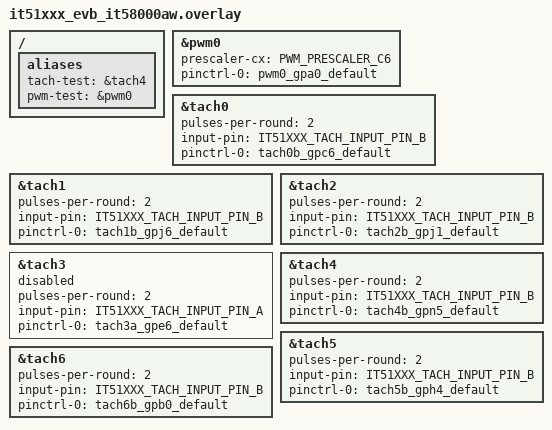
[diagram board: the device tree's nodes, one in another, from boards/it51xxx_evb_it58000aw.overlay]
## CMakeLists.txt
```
# SPDX-License-Identifier: Apache-2.0

cmake_minimum_required(VERSION 3.20.0)
find_package(Zephyr REQUIRED HINTS $ENV{ZEPHYR_BASE})
project(ite_tach)

FILE(GLOB app_sources src/*.c)
target_sources(app PRIVATE ${app_sources})
```

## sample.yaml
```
sample:
  name: ITE Tach Sensor
tests:
  sample.sensor.ite.tach:
    tags: sensors
    depends_on:
      - pwm
    platform_allow:
      - it8xxx2_evb
      - it82xx2_evb
      - it51xxx_evb/it51526aw
      - it51xxx_evb/it58000aw
```

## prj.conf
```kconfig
CONFIG_PWM=y
CONFIG_SENSOR=y
CONFIG_LOG=y
CONFIG_CBPRINTF_FP_SUPPORT=y
```

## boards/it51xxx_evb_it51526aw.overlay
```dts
/*
 * Copyright (c) 2026 ITE Corporation. All Rights Reserved.
 *
 * SPDX-License-Identifier: Apache-2.0
 */

/ {
	aliases {
		tach-test = &tach0;
		pwm-test = &pwm0;
	};
};

&pwm0 {
	status = "okay";
	prescaler-cx = <PWM_PRESCALER_C6>;
	pinctrl-0 = <&pwm0_gpa0_default>;
	pinctrl-names = "default";
};

&tach0 {
	status = "okay";
	pulses-per-round = <2>;
	/* IT51XXX_TACH_INPUT_PIN_A: tach0a_gpd6_default
	 * IT51XXX_TACH_INPUT_PIN_B: tach0b_gpc6_default
	 */
	input-pin = <IT51XXX_TACH_INPUT_PIN_B>;
	pinctrl-0 = <&tach0b_gpc6_default>;
	pinctrl-names = "default";
};
```

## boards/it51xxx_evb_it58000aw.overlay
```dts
/*
 * Copyright (c) 2026 ITE Corporation. All Rights Reserved.
 *
 * SPDX-License-Identifier: Apache-2.0
 */

/ {
	aliases {
		tach-test = &tach4;
		pwm-test = &pwm0;
	};
	/* for tach3 test */
	/*
	chosen {
		zephyr,console = &uart2;
		zephyr,shell-uart = &uart2;
	};
	*/
};

/* for tach3 test */
/*
&uart1 {
	status = "disabled";
};

&uart2 {
	status = "okay";
	current-speed = <115200>;
	clock-frequency = <1843200>;
	pinctrl-0 = <&uart2_rx_gph1_default
		     &uart2_tx_gph2_default>;
	pinctrl-names = "default";
};
*/

&pwm0 {
	status = "okay";
	prescaler-cx = <PWM_PRESCALER_C6>;
	pinctrl-0 = <&pwm0_gpa0_default>;
	pinctrl-names = "default";
};

&tach0 {
	status = "okay";
	pulses-per-round = <2>;
	/* IT51XXX_TACH_INPUT_PIN_A: tach0a_gpd6_default
	 * IT51XXX_TACH_INPUT_PIN_B: tach0b_gpc6_default
	 */
	input-pin = <IT51XXX_TACH_INPUT_PIN_B>;
	pinctrl-0 = <&tach0b_gpc6_default>;
	pinctrl-names = "default";
};

&tach1 {
	status = "okay";
	pulses-per-round = <2>;
	/* IT51XXX_TACH_INPUT_PIN_A: tach1a_gpd7_default
	 * IT51XXX_TACH_INPUT_PIN_B: tach1b_gpj6_default
	 */
	input-pin = <IT51XXX_TACH_INPUT_PIN_B>;
	pinctrl-0 = <&tach1b_gpj6_default>;
	pinctrl-names = "default";
};

&tach2 {
	status = "okay";
	pulses-per-round = <2>;
	/* IT51XXX_TACH_INPUT_PIN_A: tach2a_gpj0_default
	 * IT51XXX_TACH_INPUT_PIN_B: tach2b_gpj1_default
	 */
	input-pin = <IT51XXX_TACH_INPUT_PIN_B>;
	pinctrl-0 = <&tach2b_gpj1_default>;
	pinctrl-names = "default";
};

&tach3 {
	status = "disabled";
	pulses-per-round = <2>;
	/* IT51XXX_TACH_INPUT_PIN_A: tach3a_gpe6_default
	 * IT51XXX_TACH_INPUT_PIN_B: tach3b_gpa1_default
	 */
	input-pin = <IT51XXX_TACH_INPUT_PIN_A>;
	pinctrl-0 = <&tach3a_gpe6_default>;
	pinctrl-names = "default";
};

&tach4 {
	status = "okay";
	pulses-per-round = <2>;
	/* IT51XXX_TACH_INPUT_PIN_A: tach4a_gpa5_default
	 * IT51XXX_TACH_INPUT_PIN_B: tach4b_gpn5_default
	 */
	input-pin = <IT51XXX_TACH_INPUT_PIN_B>;
	pinctrl-0 = <&tach4b_gpn5_default>;
	pinctrl-names = "default";
};

&tach5 {
	status = "okay";
	pulses-per-round = <2>;
	/* IT51XXX_TACH_INPUT_PIN_A: tach5a_gph3_default
	 * IT51XXX_TACH_INPUT_PIN_B: tach5b_gph4_default
	 */
	input-pin = <IT51XXX_TACH_INPUT_PIN_B>;
	pinctrl-0 = <&tach5b_gph4_default>;
	pinctrl-names = "default";
};

&tach6 {
	status = "okay";
	pulses-per-round = <2>;
	/* IT51XXX_TACH_INPUT_PIN_A: tach6a_gpe4_default
	 * IT51XXX_TACH_INPUT_PIN_B: tach6b_gpb0_default
	 */
	input-pin = <IT51XXX_TACH_INPUT_PIN_B>;
	pinctrl-0 = <&tach6b_gpb0_default>;
	pinctrl-names = "default";
};
```

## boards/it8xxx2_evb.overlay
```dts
/*
 * Copyright (c) 2026 ITE Corporation. All Rights Reserved.
 *
 * SPDX-License-Identifier: Apache-2.0
 */

/ {
	aliases {
		tach-test = &tach0;
		pwm-test = &pwm0;
	};
};

&pwm0 {
	status = "okay";
	prescaler-cx = <PWM_PRESCALER_C6>;
	pinctrl-0 = <&pwm0_gpa0_default>;
	pinctrl-names = "default";
};

&tach0 {
	status = "okay";
	pulses-per-round = <2>;
	/* IT8XXX2_TACH_CHANNEL_A: tach0a_gpd6_default
	 * IT8XXX2_TACH_CHANNEL_B: tach0b_gpj2_default
	 */
	channel = <IT8XXX2_TACH_CHANNEL_B>;
	pinctrl-0 = <&tach0b_gpj2_default>;
	pinctrl-names = "default";
};
```

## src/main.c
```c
/*
 * Copyright (c) 2026 ITE Technology Corporation.
 *
 * SPDX-License-Identifier: Apache-2.0
 */

#include <zephyr/kernel.h>
#include <zephyr/drivers/pwm.h>
#include <zephyr/drivers/sensor.h>

#include <zephyr/logging/log.h>
#define LOG_LEVEL CONFIG_LOG_LEVEL_DBG
LOG_MODULE_REGISTER(main);

#define RPM_TO_HZ(rpm, p) (rpm * p / 60)

#define WAIT_PWM_READY_MS K_MSEC(50)

int main(void)
{
	const struct device *pwm_dev = DEVICE_DT_GET(DT_ALIAS(pwm_test));
	const struct device *fan_dev = DEVICE_DT_GET(DT_ALIAS(tach_test));
	const int pulses_per_round = DT_PROP(DT_ALIAS(tach_test), pulses_per_round);
	struct sensor_value val;
	double rpm;
	int ret;

	if (!device_is_ready(pwm_dev) || !device_is_ready(fan_dev)) {
		LOG_ERR("pwm or fan device is not ready");
		return -ENODEV;
	}

	for (int i = 1; i < 5; i++) {
		uint32_t period_ns = i * NSEC_PER_MSEC, pulse_ns = period_ns / 2;
		uint32_t expected = NSEC_PER_SEC / period_ns;

		ret = pwm_set(pwm_dev, 0, period_ns, pulse_ns, 0);
		if (ret) {
			LOG_ERR("failed to set pwm");
			return ret;
		}

		/* wait for pwm stable */
		k_sleep(WAIT_PWM_READY_MS);

		ret = sensor_sample_fetch_chan(fan_dev, SENSOR_CHAN_RPM);
		if (ret) {
			LOG_ERR("failed to fetch sample");
			return ret;
		}

		ret = sensor_channel_get(fan_dev, SENSOR_CHAN_RPM, &val);
		if (ret) {
			LOG_ERR("failed to get sensor value");
			return ret;
		}

		rpm = sensor_value_to_double(&val);
		if (rpm == 0) {
			LOG_ERR("tach pin not wired to pwm pin? (tach rpm 0)");
			return -EINVAL;
		}

		LOG_INF("rpm %.2f, freq %.2f (exp %d)", rpm, RPM_TO_HZ(rpm, pulses_per_round),
			expected);
	}

	return 0;
}
```
